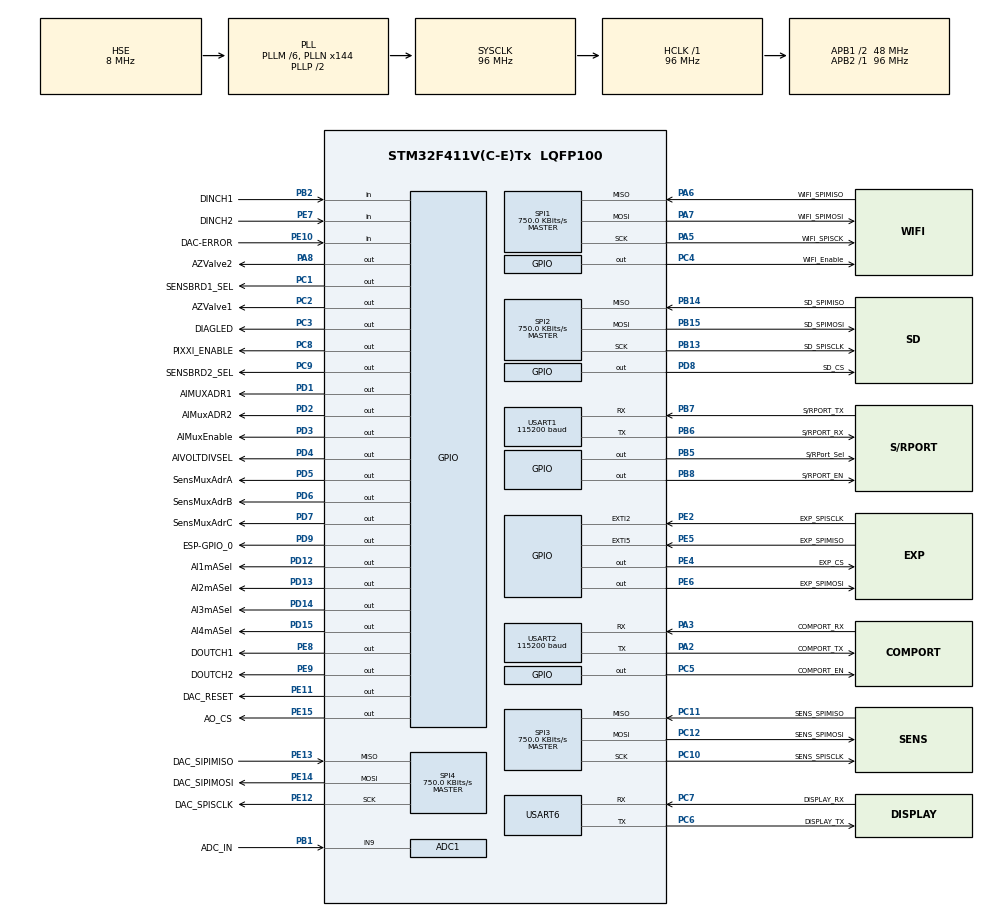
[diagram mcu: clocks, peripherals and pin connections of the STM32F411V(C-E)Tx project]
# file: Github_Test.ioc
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ADC1.Channel-14\#ChannelRegularConversion=ADC_CHANNEL_9
ADC1.ClockPrescaler=ADC_CLOCK_SYNC_PCLK_DIV4
ADC1.ContinuousConvMode=ENABLE
ADC1.DMAContinuousRequests=ENABLE
ADC1.NbrOfConversion=1
ADC1.NbrOfConversionFlag=1
ADC1.Rank-14\#ChannelRegularConversion=1
ADC1.SamplingTime-14\#ChannelRegularConversion=ADC_SAMPLETIME_3CYCLES
ADC1.master=1
Dma.ADC1.3.Direction=DMA_PERIPH_TO_MEMORY
Dma.ADC1.3.FIFOMode=DMA_FIFOMODE_DISABLE
Dma.ADC1.3.Instance=DMA2_Stream0
Dma.ADC1.3.MemDataAlignment=DMA_MDATAALIGN_HALFWORD
Dma.ADC1.3.MemInc=DMA_MINC_ENABLE
Dma.ADC1.3.Mode=DMA_CIRCULAR
Dma.ADC1.3.PeriphDataAlignment=DMA_PDATAALIGN_HALFWORD
Dma.ADC1.3.PeriphInc=DMA_PINC_DISABLE
Dma.ADC1.3.Priority=DMA_PRIORITY_LOW
Dma.Request0=USART1_RX
Dma.Request1=USART2_RX
Dma.Request2=USART6_RX
Dma.Request3=ADC1
Dma.Request4=SPI4_RX
Dma.SPI4_RX.4.Direction=DMA_PERIPH_TO_MEMORY
Dma.SPI4_RX.4.FIFOMode=DMA_FIFOMODE_DISABLE
Dma.SPI4_RX.4.Instance=DMA2_Stream3
Dma.SPI4_RX.4.MemDataAlignment=DMA_MDATAALIGN_HALFWORD
Dma.SPI4_RX.4.MemInc=DMA_MINC_ENABLE
Dma.SPI4_RX.4.Mode=DMA_CIRCULAR
Dma.SPI4_RX.4.PeriphDataAlignment=DMA_PDATAALIGN_HALFWORD
Dma.SPI4_RX.4.PeriphInc=DMA_PINC_DISABLE
Dma.SPI4_RX.4.Priority=DMA_PRIORITY_LOW
Dma.USART1_RX.0.Direction=DMA_PERIPH_TO_MEMORY
Dma.USART1_RX.0.FIFOMode=DMA_FIFOMODE_DISABLE
Dma.USART1_RX.0.Instance=DMA2_Stream2
Dma.USART1_RX.0.MemDataAlignment=DMA_MDATAALIGN_BYTE
Dma.USART1_RX.0.MemInc=DMA_MINC_ENABLE
Dma.USART1_RX.0.Mode=DMA_CIRCULAR
Dma.USART1_RX.0.PeriphDataAlignment=DMA_PDATAALIGN_BYTE
Dma.USART1_RX.0.PeriphInc=DMA_PINC_DISABLE
Dma.USART1_RX.0.Priority=DMA_PRIORITY_LOW
Dma.USART2_RX.1.Direction=DMA_PERIPH_TO_MEMORY
Dma.USART2_RX.1.FIFOMode=DMA_FIFOMODE_DISABLE
Dma.USART2_RX.1.Instance=DMA1_Stream5
Dma.USART2_RX.1.MemDataAlignment=DMA_MDATAALIGN_BYTE
Dma.USART2_RX.1.MemInc=DMA_MINC_ENABLE
Dma.USART2_RX.1.Mode=DMA_CIRCULAR
Dma.USART2_RX.1.PeriphDataAlignment=DMA_PDATAALIGN_BYTE
Dma.USART2_RX.1.PeriphInc=DMA_PINC_DISABLE
Dma.USART2_RX.1.Priority=DMA_PRIORITY_LOW
Dma.USART6_RX.2.Direction=DMA_PERIPH_TO_MEMORY
Dma.USART6_RX.2.FIFOMode=DMA_FIFOMODE_DISABLE
Dma.USART6_RX.2.Instance=DMA2_Stream1
Dma.USART6_RX.2.MemDataAlignment=DMA_MDATAALIGN_BYTE
Dma.USART6_RX.2.MemInc=DMA_MINC_ENABLE
Dma.USART6_RX.2.Mode=DMA_CIRCULAR
Dma.USART6_RX.2.PeriphDataAlignment=DMA_PDATAALIGN_BYTE
Dma.USART6_RX.2.PeriphInc=DMA_PINC_DISABLE
Dma.USART6_RX.2.Priority=DMA_PRIORITY_LOW
Mcu.Family=STM32F4
Mcu.Name=STM32F411V(C-E)Tx
Mcu.Package=LQFP100
NVIC.DMA1_Stream5_IRQn=true\:0\:0\:false\:false\:true\:false\:true
NVIC.DMA2_Stream0_IRQn=true\:0\:0\:false\:false\:true\:false\:true
NVIC.DMA2_Stream1_IRQn=true\:0\:0\:false\:false\:true\:false\:true
NVIC.DMA2_Stream2_IRQn=true\:0\:0\:false\:false\:true\:false\:true
NVIC.DMA2_Stream3_IRQn=true\:0\:0\:false\:false\:true\:false\:true
NVIC.EXTI2_IRQn=true\:0\:0\:false\:false\:true\:true\:true
NVIC.EXTI9_5_IRQn=true\:0\:0\:false\:false\:true\:true\:true
NVIC.PriorityGroup=NVIC_PRIORITYGROUP_4
NVIC.SPI4_IRQn=true\:0\:0\:false\:false\:true\:true\:true
NVIC.TIM1_BRK_TIM9_IRQn=true\:0\:0\:false\:false\:true\:true\:true
NVIC.TIM1_TRG_COM_TIM11_IRQn=true\:0\:0\:false\:false\:true\:true\:true
NVIC.TIM1_UP_TIM10_IRQn=true\:0\:0\:false\:false\:true\:true\:true
NVIC.TIM5_IRQn=true\:0\:0\:false\:false\:true\:false\:true
NVIC.TimeBase=TIM5_IRQn
NVIC.TimeBaseIP=TIM5
NVIC.USART1_IRQn=true\:0\:0\:false\:false\:true\:true\:true
NVIC.USART2_IRQn=true\:0\:0\:false\:false\:true\:true\:true
NVIC.USART6_IRQn=true\:0\:0\:false\:false\:true\:true\:true
PA13.GPIO_Label=SWDIO
PA13.Mode=Serial_Wire
PA13.Signal=SYS_JTMS-SWDIO
PA14.GPIO_Label=SWCLK
PA14.Mode=Serial_Wire
PA14.Signal=SYS_JTCK-SWCLK
PA2.GPIO_Label=COMPORT_TX
PA2.Mode=Asynchronous
PA2.Signal=USART2_TX
PA3.GPIO_Label=COMPORT_RX
PA3.Mode=Asynchronous
PA3.Signal=USART2_RX
PA5.GPIO_Label=WIFI_SPISCK
PA5.Mode=Full_Duplex_Master
PA5.Signal=SPI1_SCK
PA6.GPIO_Label=WIFI_SPIMISO
PA6.Mode=Full_Duplex_Master
PA6.Signal=SPI1_MISO
PA7.GPIO_Label=WIFI_SPIMOSI
PA7.Mode=Full_Duplex_Master
PA7.Signal=SPI1_MOSI
PA8.GPIO_Label=AZValve2
PA8.Signal=GPIO_Output
PB1.GPIO_Label=ADC_IN
PB1.Signal=ADCx_IN9
PB13.GPIO_Label=SD_SPISCLK
PB13.Mode=Full_Duplex_Master
PB13.Signal=SPI2_SCK
PB14.GPIO_Label=SD_SPIMISO
PB14.Mode=Full_Duplex_Master
PB14.Signal=SPI2_MISO
PB15.GPIO_Label=SD_SPIMOSI
PB15.Mode=Full_Duplex_Master
PB15.Signal=SPI2_MOSI
PB2.GPIO_Label=DINCH1
PB2.Signal=GPIO_Input
PB5.GPIO_Label=S/RPort_Sel
PB5.Signal=GPIO_Output
PB6.GPIO_Label=S/RPORT_RX
PB6.Mode=Asynchronous
PB6.Signal=USART1_TX
PB7.GPIO_Label=S/RPORT_TX
PB7.Mode=Asynchronous
PB7.Signal=USART1_RX
PB8.GPIO_Label=S/RPORT_EN
PB8.Signal=GPIO_Output
PC1.GPIO_Label=SENSBRD1_SEL
PC1.Signal=GPIO_Output
PC10.GPIO_Label=SENS_SPISCLK
PC10.Mode=Full_Duplex_Master
PC10.Signal=SPI3_SCK
PC11.GPIO_Label=SENS_SPIMISO
PC11.Mode=Full_Duplex_Master
PC11.Signal=SPI3_MISO
PC12.GPIO_Label=SENS_SPIMOSI
PC12.Mode=Full_Duplex_Master
PC12.Signal=SPI3_MOSI
PC14-OSC32_IN.Mode=LSE-External-Oscillator
PC14-OSC32_IN.Signal=RCC_OSC32_IN
PC15-OSC32_OUT.Mode=LSE-External-Oscillator
PC15-OSC32_OUT.Signal=RCC_OSC32_OUT
PC2.GPIO_Label=AZValve1
PC2.Signal=GPIO_Output
PC3.GPIO_Label=DIAGLED 
PC3.Signal=GPIO_Output
PC4.GPIO_Label=WIFI_Enable
PC4.Signal=GPIO_Output
PC5.GPIO_Label=COMPORT_EN
PC5.Signal=GPIO_Output
PC6.GPIO_Label=DISPLAY_TX
PC6.Mode=Asynchronous
PC6.Signal=USART6_TX
PC7.GPIO_Label=DISPLAY_RX
PC7.Mode=Asynchronous
PC7.Signal=USART6_RX
PC8.GPIO_Label=PIXXI_ENABLE
PC8.Signal=GPIO_Output
PC9.GPIO_Label=SENSBRD2_SEL
PC9.Signal=GPIO_Output
PD1.GPIO_Label=AIMUXADR1
PD1.Signal=GPIO_Output
PD12.GPIO_Label=AI1mASel
PD12.Signal=GPIO_Output
PD13.GPIO_Label=AI2mASel
PD13.Signal=GPIO_Output
PD14.GPIO_Label=AI3mASel
PD14.Signal=GPIO_Output
PD15.GPIO_Label=AI4mASel
PD15.Signal=GPIO_Output
PD2.GPIO_Label=AIMuxADR2
PD2.Signal=GPIO_Output
PD3.GPIO_Label=AIMuxEnable
PD3.Signal=GPIO_Output
PD4.GPIO_Label=AIVOLTDIVSEL
PD4.Signal=GPIO_Output
PD5.GPIO_Label=SensMuxAdrA
PD5.Signal=GPIO_Output
PD6.GPIO_Label=SensMuxAdrB
PD6.Signal=GPIO_Output
PD7.GPIO_Label=SensMuxAdrC
PD7.Signal=GPIO_Output
PD8.GPIO_Label=SD_CS
PD8.Signal=GPIO_Output
PD9.GPIO_Label=ESP-GPIO_0
PD9.Signal=GPIO_Output
PE10.GPIO_Label=DAC-ERROR
PE10.Signal=GPIO_Input
PE11.GPIO_Label=DAC_RESET
PE11.Signal=GPIO_Output
PE12.GPIO_Label=DAC_SPISCLK
PE12.Mode=Full_Duplex_Master
PE12.Signal=SPI4_SCK
PE13.GPIO_Label=DAC_SIPIMISO
PE13.Mode=Full_Duplex_Master
PE13.Signal=SPI4_MISO
PE14.GPIO_Label=DAC_SIPIMOSI
PE14.Mode=Full_Duplex_Master
PE14.Signal=SPI4_MOSI
PE15.GPIO_Label=AO_CS
PE15.Signal=GPIO_Output
PE2.GPIO_Label=EXP_SPISCLK
PE2.GPIO_ModeDefaultEXTI=GPIO_MODE_IT_RISING_FALLING
PE2.Signal=GPXTI2
PE4.GPIO_Label=EXP_CS
PE4.GPIO_Speed=GPIO_SPEED_FREQ_VERY_HIGH
PE4.Signal=GPIO_Output
PE5.GPIO_Label=EXP_SPIMISO
PE5.GPIO_ModeDefaultEXTI=GPIO_MODE_IT_RISING_FALLING
PE5.Signal=GPXTI5
PE6.GPIO_Label=EXP_SPIMOSI
PE6.GPIO_Speed=GPIO_SPEED_FREQ_VERY_HIGH
PE6.Signal=GPIO_Output
PE7.GPIO_Label=DINCH2
PE7.Signal=GPIO_Input
PE8.GPIO_Label=DOUTCH1
PE8.GPIO_PuPd=GPIO_PULLDOWN
PE8.GPIO_Speed=GPIO_SPEED_FREQ_HIGH
PE8.Signal=GPIO_Output
PE9.GPIO_Label=DOUTCH2
PE9.GPIO_PuPd=GPIO_PULLDOWN
PE9.GPIO_Speed=GPIO_SPEED_FREQ_HIGH
PE9.Signal=GPIO_Output
PH0\ -\ OSC_IN.Mode=HSE-External-Oscillator
PH0\ -\ OSC_IN.Signal=RCC_OSC_IN
PH1\ -\ OSC_OUT.Mode=HSE-External-Oscillator
PH1\ -\ OSC_OUT.Signal=RCC_OSC_OUT
ProjectManager.HeapSize=0x200
ProjectManager.StackSize=0x400
ProjectManager.TargetToolchain=STM32CubeIDE
RCC.48MHZClocksFreq_Value=38400000
RCC.AHBFreq_Value=96000000
RCC.APB1CLKDivider=RCC_HCLK_DIV2
RCC.APB1Freq_Value=48000000
RCC.APB1TimFreq_Value=96000000
RCC.APB2Freq_Value=96000000
RCC.APB2TimFreq_Value=96000000
RCC.CortexFreq_Value=96000000
RCC.HCLKFreq_Value=96000000
RCC.HSE_VALUE=8000000
RCC.HSI_VALUE=16000000
RCC.PLLM=6
RCC.PLLN=144
RCC.PLLQ=5
RCC.PLLSourceVirtual=RCC_PLLSOURCE_HSE
RCC.SYSCLKFreq_VALUE=96000000
RCC.SYSCLKSource=RCC_SYSCLKSOURCE_PLLCLK
RCC.VCOOutputFreq_Value=192000000
SH.ADCx_IN9.0=ADC1_IN9,IN9
SPI1.BaudRatePrescaler=SPI_BAUDRATEPRESCALER_128
SPI1.CalculateBaudRate=750.0 KBits/s
SPI1.Direction=SPI_DIRECTION_2LINES
SPI1.Mode=SPI_MODE_MASTER
SPI1.VirtualType=VM_MASTER
SPI2.BaudRatePrescaler=SPI_BAUDRATEPRESCALER_64
SPI2.CalculateBaudRate=750.0 KBits/s
SPI2.Direction=SPI_DIRECTION_2LINES
SPI2.Mode=SPI_MODE_MASTER
SPI2.VirtualType=VM_MASTER
SPI3.BaudRatePrescaler=SPI_BAUDRATEPRESCALER_64
SPI3.CalculateBaudRate=750.0 KBits/s
SPI3.Direction=SPI_DIRECTION_2LINES
SPI3.Mode=SPI_MODE_MASTER
SPI3.VirtualType=VM_MASTER
SPI4.BaudRatePrescaler=SPI_BAUDRATEPRESCALER_128
SPI4.CLKPhase=SPI_PHASE_1EDGE
SPI4.CLKPolarity=SPI_POLARITY_LOW
SPI4.CalculateBaudRate=750.0 KBits/s
SPI4.Direction=SPI_DIRECTION_2LINES
SPI4.Mode=SPI_MODE_MASTER
SPI4.VirtualType=VM_MASTER
TIM10.Period=4999
TIM10.Prescaler=9599
TIM11.Period=1
TIM11.Prescaler=4599
USART1.BaudRate=115200
USART1.VirtualMode=VM_ASYNC
USART2.BaudRate=115200
USART2.VirtualMode=VM_ASYNC
USART6.VirtualMode=VM_ASYNC
VP_FATFS_VS_Generic.Mode=User_defined
VP_SYS_VS_tim5.Mode=TIM5
VP_TIM10_VS_ClockSourceINT.Mode=Enable_Timer
VP_TIM11_VS_ClockSourceINT.Mode=Enable_Timer
VP_TIM9_VS_ClockSourceINT.Mode=Internal
board=custom

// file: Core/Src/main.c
/* USER CODE BEGIN Header */
/**
  ******************************************************************************
  * @file           : main.c
  * @brief          : Main program body
  ******************************************************************************
  * @attention
  *
  * <h2><center>&copy; Copyright (c) 2020 STMicroelectronics.
  * All rights reserved.</center></h2>
  *
  * This software component is licensed by ST under Ultimate Liberty license
  * SLA0044, the "License"; You may not use this file except in compliance with
  * the License. You may obtain a copy of the License at:
  *                             www.st.com/SLA0044
  *
  ******************************************************************************
  */
/* USER CODE END Header */

#include "main.h"
#include "adc.h"
#include "dma.h"
#include "fatfs.h"
#include "spi.h"
#include "tim.h"
#include "usart.h"
#include "gpio.h"

void SystemClock_Config(void);

int main(void)
{

  /* MCU Configuration--------------------------------------------------------*/

  /* Reset of all peripherals, Initializes the Flash interface and the Systick. */
  HAL_Init();

  /* Configure the system clock */
  SystemClock_Config();

  /* Initialize all configured peripherals */
  MX_GPIO_Init();
  MX_DMA_Init();
  MX_ADC1_Init();
  MX_SPI2_Init();
  MX_SPI3_Init();
  MX_SPI4_Init();
  MX_USART1_UART_Init();
  MX_USART2_UART_Init();
  MX_USART6_UART_Init();
  MX_TIM10_Init();
  MX_FATFS_Init();
  MX_TIM11_Init();
  MX_TIM9_Init();
  MX_SPI1_Init();
  /* USER CODE BEGIN 2 */
HAL_TIM_Base_Start_IT(&htim10);
uint8_t asd[]= "Hello World -10\r\n";
uint8_t sss[]= "Hollow World -1\r\n";
  /* USER CODE END 2 */

  /* Infinite loop */
  while (1)
  {

    /* USER CODE BEGIN 3 */
	  HAL_GPIO_WritePin(S_RPORT_EN_GPIO_Port, S_RPORT_EN_Pin, SET);
	  HAL_UART_Transmit(&huart1, asd, 15, 10);
	  HAL_UART_Transmit(&huart1, sss, 15, 10);
	  HAL_GPIO_WritePin(S_RPORT_EN_GPIO_Port, S_RPORT_EN_Pin, RESET);
	  HAL_Delay(1000);
  }
  /* USER CODE END 3 */
}

void SystemClock_Config(void)
{
  RCC_OscInitTypeDef RCC_OscInitStruct = {0};
  RCC_ClkInitTypeDef RCC_ClkInitStruct = {0};

  /** Configure the main internal regulator output voltage
  */
  __HAL_RCC_PWR_CLK_ENABLE();
  __HAL_PWR_VOLTAGESCALING_CONFIG(PWR_REGULATOR_VOLTAGE_SCALE1);
  /** Initializes the CPU, AHB and APB busses clocks
  */
  RCC_OscInitStruct.OscillatorType = RCC_OSCILLATORTYPE_HSE;
  RCC_OscInitStruct.HSEState = RCC_HSE_ON;
  RCC_OscInitStruct.PLL.PLLState = RCC_PLL_ON;
  RCC_OscInitStruct.PLL.PLLSource = RCC_PLLSOURCE_HSE;
  RCC_OscInitStruct.PLL.PLLM = 6;
  RCC_OscInitStruct.PLL.PLLN = 144;
  RCC_OscInitStruct.PLL.PLLP = RCC_PLLP_DIV2;
  RCC_OscInitStruct.PLL.PLLQ = 5;
  if (HAL_RCC_OscConfig(&RCC_OscInitStruct) != HAL_OK)
  {
    Error_Handler();
  }
  /** Initializes the CPU, AHB and APB busses clocks
  */
  RCC_ClkInitStruct.ClockType = RCC_CLOCKTYPE_HCLK|RCC_CLOCKTYPE_SYSCLK
                              |RCC_CLOCKTYPE_PCLK1|RCC_CLOCKTYPE_PCLK2;
  RCC_ClkInitStruct.SYSCLKSource = RCC_SYSCLKSOURCE_PLLCLK;
  RCC_ClkInitStruct.AHBCLKDivider = RCC_SYSCLK_DIV1;
  RCC_ClkInitStruct.APB1CLKDivider = RCC_HCLK_DIV2;
  RCC_ClkInitStruct.APB2CLKDivider = RCC_HCLK_DIV1;

  if (HAL_RCC_ClockConfig(&RCC_ClkInitStruct, FLASH_LATENCY_3) != HAL_OK)
  {
    Error_Handler();
  }
}

void HAL_TIM_PeriodElapsedCallback(TIM_HandleTypeDef *htim)
{
  if (htim->Instance == TIM5) {
    HAL_IncTick();
  }
}

void Error_Handler(void)
{
}

/************************ (C) COPYRIGHT STMicroelectronics *****END OF FILE****/
